# ATSAMD21E17DU register map
Vendor: Microchip Technology Inc.; File version: G
CPU: CM0+ r0p1, little endian, no MPU, no FPU, 0x2 interrupt priority bits, 0x0 interrupts
Registers are 32-bit, read-write, reset 0x0 unless marked. A register's access mark holds for its fields unless they carry their own. Offsets are from the block's base; [hi:lo] are bit positions; {n}, {i} and the like mark numbered series; 'fields as' and 'values as' point back to an identical list.

## GCLK — Generic Clock Generator
Base 0x40000C00; register names take the prefix GCLK_
0x00 CTRL 8-bit — Control
  [0] SWRST — Software Reset
0x01 STATUS 8-bit ro
  [7] SYNCBUSY — Synchronization Busy Status
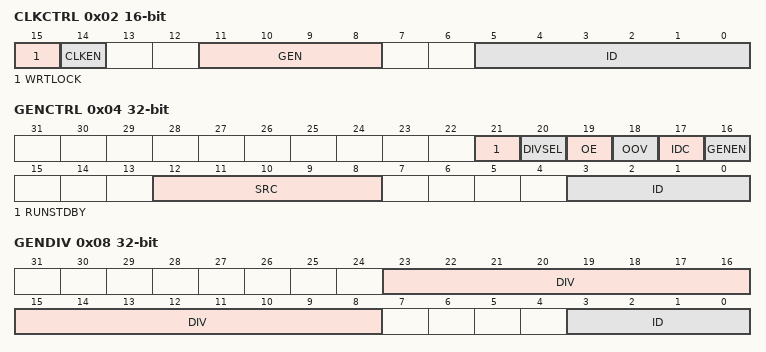
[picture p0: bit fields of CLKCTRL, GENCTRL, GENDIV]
0x02 CLKCTRL 16-bit — Generic Clock Control
  [15] WRTLOCK — Write Lock
  [14] CLKEN — Clock Enable
  [11:8] GEN — Generic Clock Generator
    {v}=GCLK{v} (Generic clock generator {v}) (v=0..7)
  [5:0] ID — Generic Clock Selection ID
    0=DFLL48; 1=FDPLL; 2=FDPLL32K; 3=WDT; 4=RTC; 5=EIC; 6=USB; {v}=EVSYS_{v-7} (v=7..18); 19=SERCOMX_SLOW; {v}=SERCOM{v-20}_CORE (v=20..25); 26=TCC0_TCC1; 27=TCC2_TC3; 28=TC4_TC5; 29=TC6_TC7; 30=ADC; 31=AC_DIG; 32=AC_ANA; 33=DAC; 35=I2S_0; 36=I2S_1
0x04 GENCTRL — Generic Clock Generator Control
  [21] RUNSTDBY — Run in Standby
  [20] DIVSEL — Divide Selection
  [19] OE — Output Enable
  [18] OOV — Output Off Value
  [17] IDC — Improve Duty Cycle
  [16] GENEN — Generic Clock Generator Enable
  [12:8] SRC — Source Select
    0=XOSC (XOSC oscillator output); 1=GCLKIN (Generator input pad); 2=GCLKGEN1 (Generic clock generator 1 output); 3=OSCULP32K (OSCULP32K oscillator output); 4=OSC32K (OSC32K oscillator output); 5=XOSC32K (XOSC32K oscillator output); 6=OSC8M (OSC8M oscillator output); 7=DFLL48M (DFLL48M output); 8=FDPLL (FDPLL output)
  [3:0] ID — Generic Clock Generator Selection
0x08 GENDIV — Generic Clock Generator Division
  [23:8] DIV — Division Factor
  [3:0] ID — Generic Clock Generator Selection

## HMATRIX — HSB Matrix
Base 0x41007000; register names take the prefix HMATRIXB_
{0x80+8i} PRAS{i} (i=0..15) — Priority A for Slave
{0x84+8i} PRBS{i} (i=0..15) — Priority B for Slave
{0x110+4i} SFR{i} (i=0..15) — Special Function
  [31:0] SFR — Special Function Register

## MTB — Cortex-M0+ Micro-Trace Buffer
Base 0x41006000; register names take the prefix MTB_
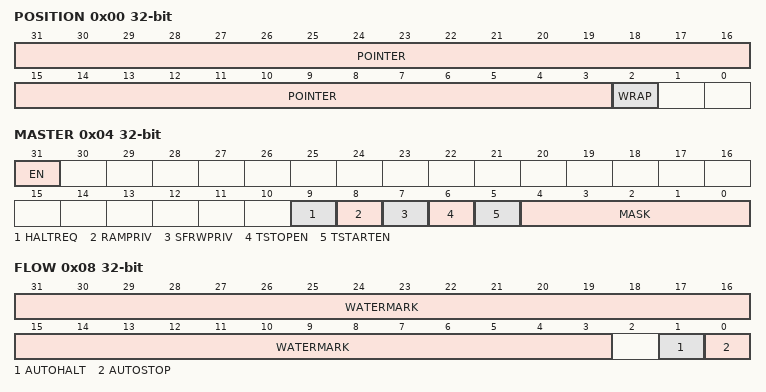
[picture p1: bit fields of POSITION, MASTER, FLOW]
0x00 POSITION — MTB Position
  [31:3] POINTER — Trace Packet Location Pointer
  [2] WRAP — Pointer Value Wraps
0x04 MASTER — MTB Master
  [31] EN — Main Trace Enable
  [9] HALTREQ — Halt Request
  [8] RAMPRIV — SRAM Privilege
  [7] SFRWPRIV — Special Function Register Write Privilege
  [6] TSTOPEN — Trace Stop Input Enable
  [5] TSTARTEN — Trace Start Input Enable
  [4:0] MASK — Maximum Value of the Trace Buffer in SRAM
0x08 FLOW — MTB Flow
  [31:3] WATERMARK — Watermark value
  [1] AUTOHALT — Auto Halt Request
  [0] AUTOSTOP — Auto Stop Tracing
0x0C BASE ro — MTB Base
0xF00 ITCTRL — MTB Integration Mode Control
0xFA0 CLAIMSET — MTB Claim Set
0xFA4 CLAIMCLR — MTB Claim Clear
0xFB0 LOCKACCESS — MTB Lock Access
0xFB4 LOCKSTATUS ro — MTB Lock Status
0xFB8 AUTHSTATUS ro — MTB Authentication Status
0xFBC DEVARCH ro — MTB Device Architecture
0xFC8 DEVID ro — MTB Device Configuration
0xFCC DEVTYPE ro — MTB Device Type
{0xFC0+4i} PID{i} ro (i=4..7) — CoreSight
{0xFE0+4i} PID{i} ro (i=0..3) — CoreSight
{0xFF0+4i} CID{i} ro (i=0..3) — CoreSight

## PAC0 — Peripheral Access Controller 0
Base 0x40000000; register names take the prefix PAC_
0x00 WPCLR — Write Protection Clear
  [31:1] WP
0x04 WPSET — Write Protection Set
  [31:1] WP

## PAC1 — Peripheral Access Controller 1
Base 0x41000000; register names take the prefix PAC_
Registers as PAC0.

## PAC2 — Peripheral Access Controller 2
Base 0x42000000; register names take the prefix PAC_
Registers as PAC0.

## PM — Power Manager
Base 0x40000400; register names take the prefix PM_
0x00 CTRL 8-bit — Control
0x01 SLEEP 8-bit — Sleep Mode
  [1:0] IDLE — Idle Mode Configuration
    0=CPU (The CPU clock domain is stopped); 1=AHB (The CPU and AHB clock domains are stopped); 2=APB (The CPU, AHB and APB clock domains are stopped)
0x02 EXTCTRL 8-bit — External Reset Controller
  [0] SETDIS — External Reset Disable
0x08 CPUSEL 8-bit — CPU Clock Select
  [2:0] CPUDIV — CPU Prescaler Selection
    0=DIV1 (Divide by 1); 1=DIV2 (Divide by 2); 2=DIV4 (Divide by 4); 3=DIV8 (Divide by 8); 4=DIV16 (Divide by 16); 5=DIV32 (Divide by 32); 6=DIV64 (Divide by 64); 7=DIV128 (Divide by 128)
0x09 APBASEL 8-bit — APBA Clock Select
  [2:0] APBADIV — APBA Prescaler Selection
    values as CPUSEL.CPUDIV
0x0A APBBSEL 8-bit — APBB Clock Select
  [2:0] APBBDIV — APBB Prescaler Selection
    values as CPUSEL.CPUDIV
0x0B APBCSEL 8-bit — APBC Clock Select
  [2:0] APBCDIV — APBC Prescaler Selection
    values as CPUSEL.CPUDIV
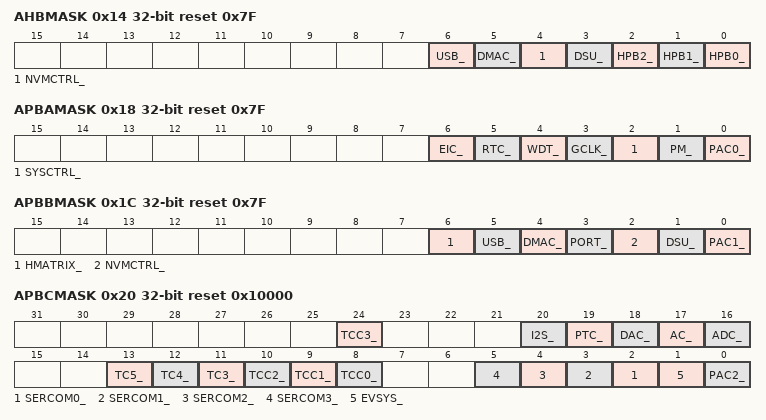
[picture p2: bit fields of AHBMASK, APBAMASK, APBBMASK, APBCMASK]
0x14 AHBMASK reset 0x7F
  [6] USB_ — USB AHB Clock Mask
  [5] DMAC_ — DMAC AHB Clock Mask
  [4] NVMCTRL_ — NVMCTRL AHB Clock Mask
  [3] DSU_ — DSU AHB Clock Mask
  [2] HPB2_ — HPB2 AHB Clock Mask
  [1] HPB1_ — HPB1 AHB Clock Mask
  [0] HPB0_ — HPB0 AHB Clock Mask
0x18 APBAMASK reset 0x7F
  [6] EIC_ — EIC APB Clock Enable
  [5] RTC_ — RTC APB Clock Enable
  [4] WDT_ — WDT APB Clock Enable
  [3] GCLK_ — GCLK APB Clock Enable
  [2] SYSCTRL_ — SYSCTRL APB Clock Enable
  [1] PM_ — PM APB Clock Enable
  [0] PAC0_ — PAC0 APB Clock Enable
0x1C APBBMASK reset 0x7F
  [6] HMATRIX_ — HMATRIX APB Clock Enable
  [5] USB_ — USB APB Clock Enable
  [4] DMAC_ — DMAC APB Clock Enable
  [3] PORT_ — PORT APB Clock Enable
  [2] NVMCTRL_ — NVMCTRL APB Clock Enable
  [1] DSU_ — DSU APB Clock Enable
  [0] PAC1_ — PAC1 APB Clock Enable
0x20 APBCMASK reset 0x10000
  [24] TCC3_ — TCC3 APB Clock Enable
  [20] I2S_ — I2S APB Clock Enable
  [19] PTC_ — PTC APB Clock Enable
  [18] DAC_ — DAC APB Clock Enable
  [17] AC_ — AC APB Clock Enable
  [16] ADC_ — ADC APB Clock Enable
  [13] TC5_ — TC5 APB Clock Enable
  [12] TC4_ — TC4 APB Clock Enable
  [11] TC3_ — TC3 APB Clock Enable
  [10] TCC2_ — TCC2 APB Clock Enable
  [9] TCC1_ — TCC1 APB Clock Enable
  [8] TCC0_ — TCC0 APB Clock Enable
  [n+2] SERCOM{n}_ (n=0..3) — SERCOM{n} APB Clock Enable
  [1] EVSYS_ — EVSYS APB Clock Enable
  [0] PAC2_ — PAC2 APB Clock Enable
0x34 INTENCLR 8-bit — Interrupt Enable Clear
  [0] CKRDY — Clock Ready Interrupt Enable
0x35 INTENSET 8-bit — Interrupt Enable Set
  [0] CKRDY — Clock Ready Interrupt Enable
0x36 INTFLAG 8-bit — Interrupt Flag Status and Clear
  [0] CKRDY — Clock Ready
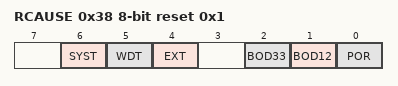
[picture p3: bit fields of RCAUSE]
0x38 RCAUSE 8-bit ro reset 0x1 — Reset Cause
  [6] SYST — System Reset Request
  [5] WDT — Watchdog Reset
  [4] EXT — External Reset
  [2] BOD33 — Brown Out 33 Detector Reset
  [1] BOD12 — Brown Out 12 Detector Reset
  [0] POR — Power On Reset
